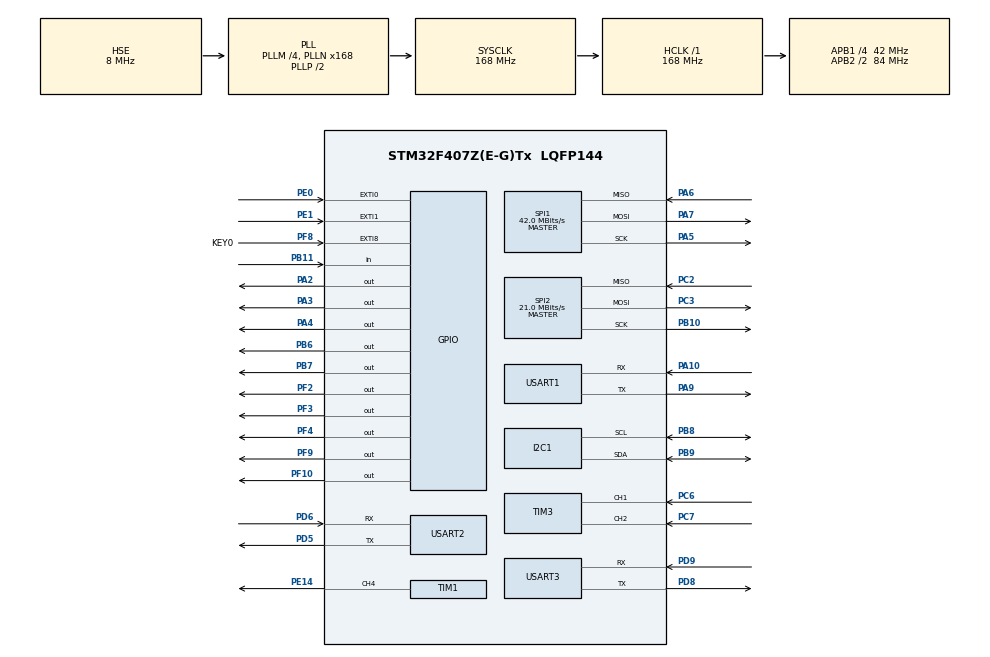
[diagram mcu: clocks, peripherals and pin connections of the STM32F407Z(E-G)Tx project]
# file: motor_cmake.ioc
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Dma.Request0=USART2_RX
Dma.Request1=USART3_RX
Dma.Request2=USART3_TX
Dma.USART2_RX.0.Direction=DMA_PERIPH_TO_MEMORY
Dma.USART2_RX.0.FIFOMode=DMA_FIFOMODE_DISABLE
Dma.USART2_RX.0.Instance=DMA1_Stream5
Dma.USART2_RX.0.MemDataAlignment=DMA_MDATAALIGN_BYTE
Dma.USART2_RX.0.MemInc=DMA_MINC_ENABLE
Dma.USART2_RX.0.Mode=DMA_CIRCULAR
Dma.USART2_RX.0.PeriphDataAlignment=DMA_PDATAALIGN_BYTE
Dma.USART2_RX.0.PeriphInc=DMA_PINC_DISABLE
Dma.USART2_RX.0.Priority=DMA_PRIORITY_HIGH
Dma.USART3_RX.1.Direction=DMA_PERIPH_TO_MEMORY
Dma.USART3_RX.1.FIFOMode=DMA_FIFOMODE_DISABLE
Dma.USART3_RX.1.Instance=DMA1_Stream1
Dma.USART3_RX.1.MemDataAlignment=DMA_MDATAALIGN_BYTE
Dma.USART3_RX.1.MemInc=DMA_MINC_ENABLE
Dma.USART3_RX.1.Mode=DMA_CIRCULAR
Dma.USART3_RX.1.PeriphDataAlignment=DMA_PDATAALIGN_BYTE
Dma.USART3_RX.1.PeriphInc=DMA_PINC_DISABLE
Dma.USART3_RX.1.Priority=DMA_PRIORITY_HIGH
Dma.USART3_TX.2.Direction=DMA_MEMORY_TO_PERIPH
Dma.USART3_TX.2.FIFOMode=DMA_FIFOMODE_DISABLE
Dma.USART3_TX.2.Instance=DMA1_Stream3
Dma.USART3_TX.2.MemDataAlignment=DMA_MDATAALIGN_BYTE
Dma.USART3_TX.2.MemInc=DMA_MINC_ENABLE
Dma.USART3_TX.2.Mode=DMA_NORMAL
Dma.USART3_TX.2.PeriphDataAlignment=DMA_PDATAALIGN_BYTE
Dma.USART3_TX.2.PeriphInc=DMA_PINC_DISABLE
Dma.USART3_TX.2.Priority=DMA_PRIORITY_LOW
Mcu.Family=STM32F4
Mcu.Name=STM32F407Z(E-G)Tx
Mcu.Package=LQFP144
NVIC.DMA1_Stream1_IRQn=true\:0\:0\:false\:false\:true\:false\:true\:true
NVIC.DMA1_Stream3_IRQn=true\:0\:0\:false\:false\:true\:false\:true\:true
NVIC.DMA1_Stream5_IRQn=true\:0\:0\:false\:false\:true\:false\:true\:true
NVIC.EXTI0_IRQn=true\:0\:0\:false\:false\:true\:true\:true\:true
NVIC.EXTI1_IRQn=true\:0\:0\:false\:false\:true\:true\:true\:true
NVIC.PriorityGroup=NVIC_PRIORITYGROUP_4
NVIC.TIM1_BRK_TIM9_IRQn=true\:0\:0\:false\:false\:true\:true\:true\:true
NVIC.TIM1_CC_IRQn=true\:0\:0\:false\:false\:true\:true\:true\:true
NVIC.TIM1_TRG_COM_TIM11_IRQn=true\:0\:0\:false\:false\:true\:true\:true\:true
NVIC.TIM1_UP_TIM10_IRQn=true\:0\:0\:false\:false\:true\:true\:true\:true
NVIC.TIM3_IRQn=true\:0\:0\:false\:false\:true\:true\:true\:true
NVIC.TIM4_IRQn=true\:0\:0\:false\:false\:true\:true\:true\:true
NVIC.USART1_IRQn=true\:0\:0\:false\:false\:true\:true\:true\:true
NVIC.USART2_IRQn=true\:0\:0\:false\:false\:true\:true\:true\:true
NVIC.USART3_IRQn=true\:0\:0\:false\:false\:true\:true\:true\:true
PA10.Mode=Asynchronous
PA10.Signal=USART1_RX
PA13.Mode=Serial_Wire
PA13.Signal=SYS_JTMS-SWDIO
PA14.Mode=Serial_Wire
PA14.Signal=SYS_JTCK-SWCLK
PA2.Signal=GPIO_Output
PA3.Signal=GPIO_Output
PA4.Signal=GPIO_Output
PA5.Mode=Full_Duplex_Master
PA5.Signal=SPI1_SCK
PA6.Mode=Full_Duplex_Master
PA6.Signal=SPI1_MISO
PA7.Mode=Full_Duplex_Master
PA7.Signal=SPI1_MOSI
PA9.Mode=Asynchronous
PA9.Signal=USART1_TX
PB10.Mode=Full_Duplex_Master
PB10.Signal=SPI2_SCK
PB11.Signal=GPIO_Input
PB6.Signal=GPIO_Output
PB7.Signal=GPIO_Output
PB8.Mode=I2C
PB8.Signal=I2C1_SCL
PB9.Mode=I2C
PB9.Signal=I2C1_SDA
PC2.Mode=Full_Duplex_Master
PC2.Signal=SPI2_MISO
PC3.Mode=Full_Duplex_Master
PC3.Signal=SPI2_MOSI
PC6.Signal=S_TIM3_CH1
PC7.Signal=S_TIM3_CH2
PD5.Mode=Asynchronous
PD5.Signal=USART2_TX
PD6.Mode=Asynchronous
PD6.Signal=USART2_RX
PD8.Mode=Asynchronous
PD8.Signal=USART3_TX
PD9.GPIO_PuPd=GPIO_PULLUP
PD9.Mode=Asynchronous
PD9.Signal=USART3_RX
PE0.GPIO_PuPd=GPIO_PULLUP
PE0.Signal=GPXTI0
PE1.Signal=GPXTI1
PE14.Signal=S_TIM1_CH4
PF10.Signal=GPIO_Output
PF2.Signal=GPIO_Output
PF3.Signal=GPIO_Output
PF4.Signal=GPIO_Output
PF8.GPIO_Label=KEY0
PF8.Signal=GPXTI8
PF9.Signal=GPIO_Output
PH0-OSC_IN.Mode=HSE-External-Oscillator
PH0-OSC_IN.Signal=RCC_OSC_IN
PH1-OSC_OUT.Mode=HSE-External-Oscillator
PH1-OSC_OUT.Signal=RCC_OSC_OUT
ProjectManager.HeapSize=0x200
ProjectManager.StackSize=0x400
ProjectManager.TargetToolchain=CMake
RCC.48MHZClocksFreq_Value=84000000
RCC.AHBFreq_Value=168000000
RCC.APB1CLKDivider=RCC_HCLK_DIV4
RCC.APB1Freq_Value=42000000
RCC.APB1TimFreq_Value=84000000
RCC.APB2CLKDivider=RCC_HCLK_DIV2
RCC.APB2Freq_Value=84000000
RCC.APB2TimFreq_Value=168000000
RCC.CortexFreq_Value=168000000
RCC.HCLKFreq_Value=168000000
RCC.HSE_VALUE=8000000
RCC.HSI_VALUE=16000000
RCC.LSE_VALUE=32768
RCC.PLLM=4
RCC.PLLN=168
RCC.PLLSourceVirtual=RCC_PLLSOURCE_HSE
RCC.SYSCLKFreq_VALUE=168000000
RCC.SYSCLKSource=RCC_SYSCLKSOURCE_PLLCLK
RCC.VCOOutputFreq_Value=336000000
SH.S_TIM1_CH4.0=TIM1_CH4,PWM Generation4 CH4
SH.S_TIM3_CH1.0=TIM3_CH1,Encoder_Interface
SH.S_TIM3_CH2.0=TIM3_CH2,Encoder_Interface
SPI1.CalculateBaudRate=42.0 MBits/s
SPI1.Direction=SPI_DIRECTION_2LINES
SPI1.Mode=SPI_MODE_MASTER
SPI1.VirtualType=VM_MASTER
SPI2.CalculateBaudRate=21.0 MBits/s
SPI2.Direction=SPI_DIRECTION_2LINES
SPI2.Mode=SPI_MODE_MASTER
SPI2.VirtualType=VM_MASTER
TIM1.AutoReloadPreload=TIM_AUTORELOAD_PRELOAD_ENABLE
TIM1.Channel-PWM\ Generation4\ CH4=TIM_CHANNEL_4
TIM3.AutoReloadPreload=TIM_AUTORELOAD_PRELOAD_ENABLE
TIM3.EncoderMode=TIM_ENCODERMODE_TI12
TIM4.AutoReloadPreload=TIM_AUTORELOAD_PRELOAD_ENABLE
TIM8.AutoReloadPreload=TIM_AUTORELOAD_PRELOAD_ENABLE
USART1.VirtualMode=VM_ASYNC
USART2.VirtualMode=VM_ASYNC
USART3.VirtualMode=VM_ASYNC
VP_TIM1_VS_ClockSourceINT.Mode=Internal
VP_TIM4_VS_ClockSourceINT.Mode=Internal
VP_TIM8_VS_ClockSourceINT.Mode=Internal
board=custom

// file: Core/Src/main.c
/* USER CODE BEGIN Header */
/**
 ******************************************************************************
 * @file           : main.c
 * @brief          : Main program body
 ******************************************************************************
 * @attention
 *
 * Copyright (c) 2025 STMicroelectronics.
 * All rights reserved.
 *
 * This software is licensed under terms that can be found in the LICENSE file
 * in the root directory of this software component.
 * If no LICENSE file comes with this software, it is provided AS-IS.
 *
 ******************************************************************************
 */
/* USER CODE END Header */
#include "main.h"
#include "dma.h"
#include "i2c.h"
#include "spi.h"
#include "tim.h"
#include "usart.h"
#include "gpio.h"

/* USER CODE BEGIN Includes */
#include <stdio.h>
#include "test_main.h"
/* USER CODE END Includes */

void SystemClock_Config(void);

int main(void)
{

    /* MCU Configuration--------------------------------------------------------*/

    /* Reset of all peripherals, Initializes the Flash interface and the Systick. */
    HAL_Init();

    /* Configure the system clock */
    SystemClock_Config();

    /* Initialize all configured peripherals */
    MX_GPIO_Init();
    MX_DMA_Init();
    MX_I2C1_Init();
    MX_SPI1_Init();
    MX_USART1_UART_Init();
    MX_TIM1_Init();
    MX_TIM3_Init();
    MX_SPI2_Init();
    MX_TIM4_Init();
    MX_TIM8_Init();
    MX_USART2_UART_Init();
    MX_USART3_UART_Init();
    /* USER CODE BEGIN 2 */
    test_main();

    /* USER CODE END 2 */

    /* Infinite loop */
    while (1)
    {

        /* USER CODE BEGIN 3 */
        HAL_GPIO_TogglePin(GPIOF, GPIO_PIN_9);
        HAL_GPIO_TogglePin(GPIOF, GPIO_PIN_10);
        // printf("hello clion\n");
        HAL_Delay(500);
    }
    /* USER CODE END 3 */
}

void SystemClock_Config(void)
{
    RCC_OscInitTypeDef RCC_OscInitStruct = {0};
    RCC_ClkInitTypeDef RCC_ClkInitStruct = {0};

    /** Configure the main internal regulator output voltage
     */
    __HAL_RCC_PWR_CLK_ENABLE();
    __HAL_PWR_VOLTAGESCALING_CONFIG(PWR_REGULATOR_VOLTAGE_SCALE1);

    /** Initializes the RCC Oscillators according to the specified parameters
     * in the RCC_OscInitTypeDef structure.
     */
    RCC_OscInitStruct.OscillatorType = RCC_OSCILLATORTYPE_HSE;
    RCC_OscInitStruct.HSEState = RCC_HSE_ON;
    RCC_OscInitStruct.PLL.PLLState = RCC_PLL_ON;
    RCC_OscInitStruct.PLL.PLLSource = RCC_PLLSOURCE_HSE;
    RCC_OscInitStruct.PLL.PLLM = 4;
    RCC_OscInitStruct.PLL.PLLN = 168;
    RCC_OscInitStruct.PLL.PLLP = RCC_PLLP_DIV2;
    RCC_OscInitStruct.PLL.PLLQ = 4;
    if (HAL_RCC_OscConfig(&RCC_OscInitStruct) != HAL_OK)
    {
        Error_Handler();
    }

    /** Initializes the CPU, AHB and APB buses clocks
     */
    RCC_ClkInitStruct.ClockType =
        RCC_CLOCKTYPE_HCLK | RCC_CLOCKTYPE_SYSCLK | RCC_CLOCKTYPE_PCLK1 | RCC_CLOCKTYPE_PCLK2;
    RCC_ClkInitStruct.SYSCLKSource = RCC_SYSCLKSOURCE_PLLCLK;
    RCC_ClkInitStruct.AHBCLKDivider = RCC_SYSCLK_DIV1;
    RCC_ClkInitStruct.APB1CLKDivider = RCC_HCLK_DIV4;
    RCC_ClkInitStruct.APB2CLKDivider = RCC_HCLK_DIV2;

    if (HAL_RCC_ClockConfig(&RCC_ClkInitStruct, FLASH_LATENCY_5) != HAL_OK)
    {
        Error_Handler();
    }
}

void Error_Handler(void)
{
    __disable_irq();
    while (1)
    {
    }
}
